# SKEAZN642 register map
Vendor: Freescale Semiconductor, Inc.; File version: 1.6
CPU: CM0PLUS r0p0, little endian, no MPU, no FPU, 0x2 interrupt priority bits, 0x0 interrupts
Registers are 32-bit, read-write, reset 0x0 unless marked. A register's access mark holds for its fields unless they carry their own. Offsets are from the block's base; [hi:lo] are bit positions; {n}, {i} and the like mark numbered series.

## SysTick — System timer
Base 0xE000E010; register names take the prefix SYST_
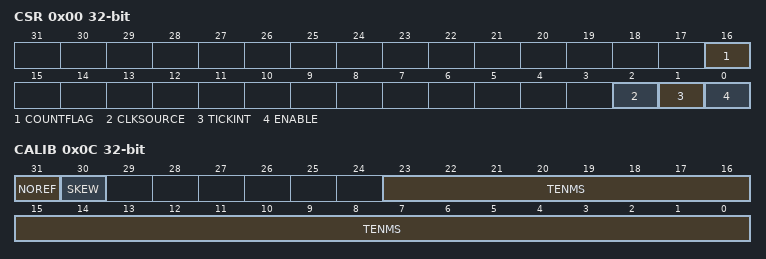
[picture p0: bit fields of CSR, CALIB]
0x00 CSR — SysTick Control and Status Register
  [16] COUNTFLAG
  [2] CLKSOURCE
    0=external clock; 1=processor clock
  [1] TICKINT
    0=counting down to 0 does not assert the SysTick exception request; 1=counting down to 0 asserts the SysTick exception request
  [0] ENABLE
    0=counter disabled; 1=counter enabled
0x04 RVR — SysTick Reload Value Register
  [23:0] RELOAD — Value to load into the SysTick Current Value Register when the counter reaches 0
0x08 CVR — SysTick Current Value Register
  [23:0] CURRENT — Current value at the time the register is accessed
0x0C CALIB ro — SysTick Calibration Value Register
  [31] NOREF
    0=The reference clock is provided; 1=The reference clock is not provided
  [30] SKEW
    0=10ms calibration value is exact; 1=10ms calibration value is inexact, because of the clock frequency
  [23:0] TENMS — Reload value to use for 10ms timing

## NVIC — Nested Vectored Interrupt Controller
Base 0xE000E100
0x00 NVIC_ISER — Interrupt Set Enable Register
  [31:0] SETENA — Interrupt set enable bits
0x80 NVIC_ICER — Interrupt Clear Enable Register
  [31:0] CLRENA — Interrupt clear-enable bits
0x100 NVIC_ISPR — Interrupt Set Pending Register
  [31:0] SETPEND — Interrupt set-pending bits
0x180 NVIC_ICPR — Interrupt Clear Pending Register
  [31:0] CLRPEND — Interrupt clear-pending bits
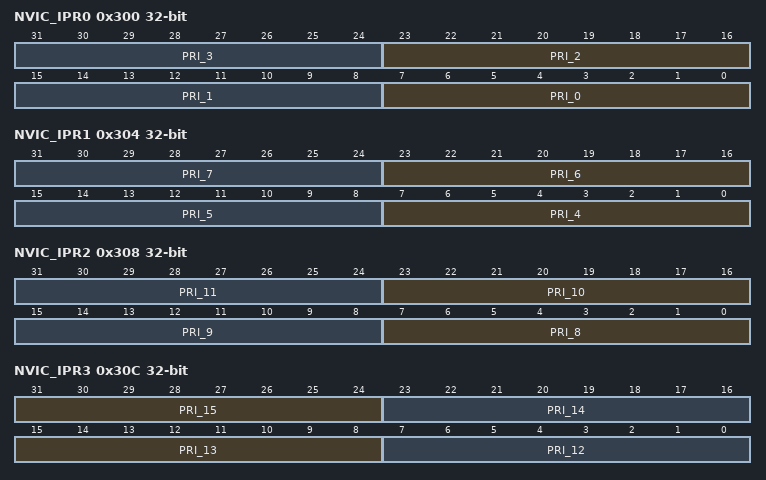
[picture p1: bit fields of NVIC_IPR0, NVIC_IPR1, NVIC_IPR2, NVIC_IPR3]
0x300 NVIC_IPR0 — Interrupt Priority Register n
  [8n+7:8n] PRI_{n} (n=0..3) — Priority of interrupt {n}
0x304 NVIC_IPR1 — Interrupt Priority Register n
  [8n-25:8n-32] PRI_{n} (n=4..7) — Priority of interrupt {n}
0x308 NVIC_IPR2 — Interrupt Priority Register n
  [8n-57:8n-64] PRI_{n} (n=8..11) — Priority of interrupt {n}
0x30C NVIC_IPR3 — Interrupt Priority Register n
  [31:24] PRI_15 — Priority of interrupt 15
  [23:16] PRI_14 — Priority of interrupt 14
  [15:8] PRI_13 — Priority of interrupt 12
  [7:0] PRI_12 — Priority of interrupt 11
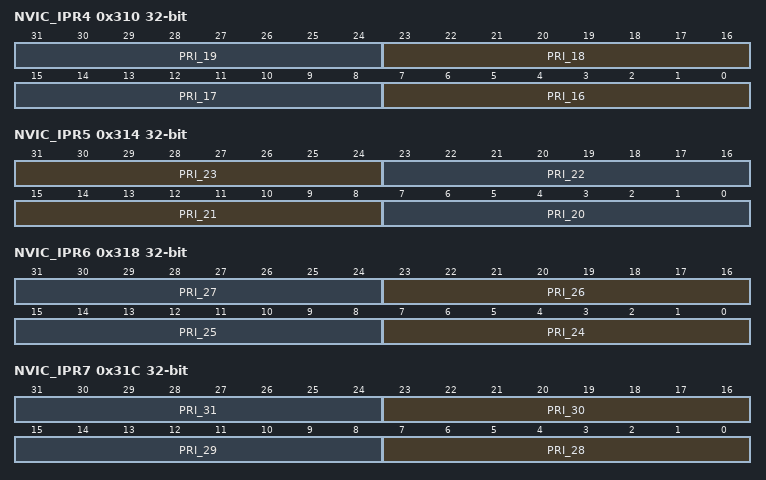
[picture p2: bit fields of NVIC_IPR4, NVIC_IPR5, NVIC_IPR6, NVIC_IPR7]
0x310 NVIC_IPR4 — Interrupt Priority Register n
  [8n-121:8n-128] PRI_{n} (n=16..19) — Priority of interrupt {n+1}
0x314 NVIC_IPR5 — Interrupt Priority Register n
  [31:24] PRI_23 — Priority of interrupt 23
  [23:16] PRI_22 — Priority of interrupt 22
  [15:8] PRI_21 — Priority of interrupt 21
  [7:0] PRI_20 — Priority of interrupt 0
0x318 NVIC_IPR6 — Interrupt Priority Register n
  [8n-185:8n-192] PRI_{n} (n=24..27) — Priority of interrupt {n}
0x31C NVIC_IPR7 — Interrupt Priority Register n
  [8n-217:8n-224] PRI_{n} (n=28..31) — Priority of interrupt {n}

## ROM — System ROM
Base 0xF0002000; register names take the prefix ROM_
0x00 ENTRY ro reset not defined
0x04 TABLEMARK ro — End of Table Marker Register
  [31:0] MARK
0xFCC SYSACCESS ro reset 0x1 — System Access Register
{0xFC0+4i} PERIPHID{i} ro reset not defined (i=4..7) — Peripheral ID Register
  [31:0] PERIPHID
{0xFE0+4i} PERIPHID{i} ro reset not defined (i=0..3) — Peripheral ID Register
  [31:0] PERIPHID
{0xFF0+4i} COMPID{i} ro reset not defined (i=0..3) — Component ID Register
  [31:0] COMPID — Component ID

## MCM — Core Platform Miscellaneous Control Module
Base 0xF0003000; register names take the prefix MCM_
0x08 PLASC 16-bit ro reset 0x7 — Crossbar Switch (AXBS) Slave Configuration
  [7:0] ASC — Each bit in the ASC field indicates whether there is a corresponding connection to the crossbar switch's slave input port.
    0=A bus slave connection to AXBS input port n is absent; 1=A bus slave connection to AXBS input port n is present
0x0A PLAMC 16-bit ro reset 0x1 — Crossbar Switch (AXBS) Master Configuration
  [7:0] AMC — Each bit in the AMC field indicates whether there is a corresponding connection to the AXBS master input port.
    0=A bus master connection to AXBS input port n is absent; 1=A bus master connection to AXBS input port n is present
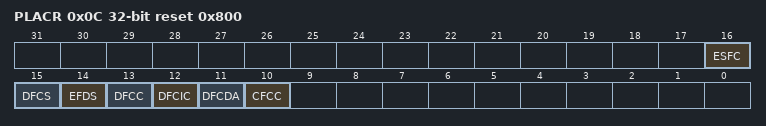
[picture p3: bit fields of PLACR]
0x0C PLACR reset 0x800 — Platform Control Register
  [16] ESFC — Enable Stalling Flash Controller
    0=Disable stalling flash controller when flash is busy; 1=Enable stalling flash controller when flash is busy
  [15] DFCS — Disable Flash Controller Speculation
    0=Enable flash controller speculation; 1=Disable flash controller speculation
  [14] EFDS — Enable Flash Data Speculation
    0=Disable flash data speculation; 1=Enable flash data speculation
  [13] DFCC — Disable Flash Controller Cache
    0=Enable flash controller cache; 1=Disable flash controller cache
  [12] DFCIC — Disable Flash Controller Instruction Caching
    0=Enable flash controller instruction caching; 1=Disable flash controller instruction caching
  [11] DFCDA — Disable Flash Controller Data Caching
    0=Enable flash controller data caching; 1=Disable flash controller data caching
  [10] CFCC wo — Clear Flash Controller Cache
